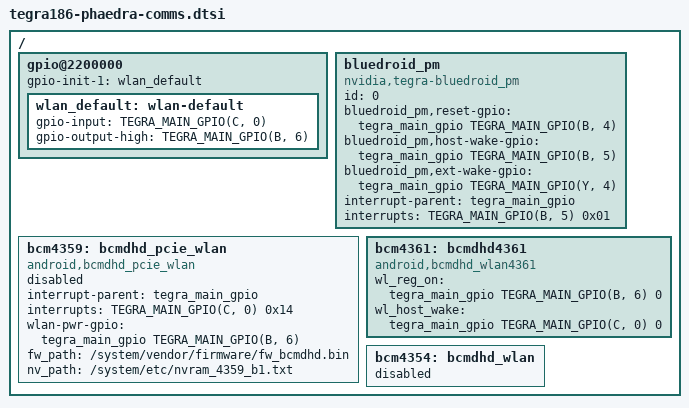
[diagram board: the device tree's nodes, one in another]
/*
 * tegra186-phaedra-comms.dtsi
 *
 * Main device tree for the phaedra product.
 *
 * Copyright (c) 2016, Magic Leap, Inc.  All rights reserved.
 *
 * This program is free software; you can redistribute it and/or modify
 * it under the terms of the GNU General Public License as published by
 * the Free Software Foundation; version 2 of the License.
 *
 * This program is distributed in the hope that it will be useful, but WITHOUT
 * ANY WARRANTY; without even the implied warranty of MERCHANTABILITY or
 * FITNESS FOR A PARTICULAR PURPOSE.  See the GNU General Public License for
 * more details.
 */
#include <dt-bindings/gpio/tegra-gpio.h>

/ {
	/* Need to enable wifi_en pin during boot for PCIe enumeration */
	gpio@2200000 {
		gpio-init-1 = <&wlan_default>;

		wlan_default: wlan-default {
			gpio-input = <TEGRA_MAIN_GPIO(C, 0)>;
			gpio-output-high = <TEGRA_MAIN_GPIO(B, 6)>;
		};
	};
	bluedroid_pm {
		compatible = "nvidia,tegra-bluedroid_pm";
		id = <0>;
		bluedroid_pm,reset-gpio = <&tegra_main_gpio TEGRA_MAIN_GPIO(B, 4) 0>;
		bluedroid_pm,host-wake-gpio = <&tegra_main_gpio TEGRA_MAIN_GPIO(B, 5) 0>;
		bluedroid_pm,ext-wake-gpio = <&tegra_main_gpio TEGRA_MAIN_GPIO(Y, 4) 0>;
		interrupt-parent = <&tegra_main_gpio>;
		interrupts = <TEGRA_MAIN_GPIO(B, 5) 0x01>;
		status = "okay";
	};

	bcm4359: bcmdhd_pcie_wlan {
		compatible = "android,bcmdhd_pcie_wlan";
		interrupt-parent = <&tegra_main_gpio>;
		interrupts = <TEGRA_MAIN_GPIO(C, 0) 0x14>;
		wlan-pwr-gpio = <&tegra_main_gpio TEGRA_MAIN_GPIO(B, 6) 0>;
		fw_path = "/system/vendor/firmware/fw_bcmdhd.bin";
		nv_path = "/system/etc/nvram_4359_b1.txt";
		status = "disabled";
	};

	bcm4361: bcmdhd4361 {
		compatible = "android,bcmdhd_wlan4361";
		wl_reg_on = <&tegra_main_gpio TEGRA_MAIN_GPIO(B, 6) 0>;
		wl_host_wake = <&tegra_main_gpio TEGRA_MAIN_GPIO(C, 0) 0>;
		status = "okay";
	};

	/* No 4354 support in Phaedra */
	bcm4354: bcmdhd_wlan {
		status = "disabled";
	};
};
